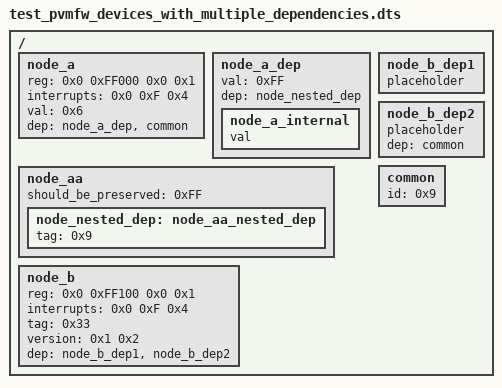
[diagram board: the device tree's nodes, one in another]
/dts-v1/;

/include/ "test_crosvm_dt_base.dtsi"

/ {
    node_a: node_a {
        reg = <0x0 0xFF000 0x0 0x1>;
        interrupts = <0x0 0xF 0x4>;
        val = <0x6>;
        dep = <&node_a_dep &common>;
    };

    node_a_dep: node_a_dep {
        val = <0xFF>;
        dep = <&node_nested_dep>;

        node_a_internal {
            val;
        };
    };

    node_aa {
        should_be_preserved = <0xFF>;
        node_nested_dep: node_aa_nested_dep {
            tag = <0x9>;
        };
    };

    node_b: node_b {
        reg = <0x0 0xFF100 0x0 0x1>;
        interrupts = <0x0 0xF 0x4>;
        tag = <0x33>;
        version = <0x1 0x2>;
        phandle = <0x5>;
        dep = <&node_b_dep1 &node_b_dep2>;
    };

    node_b_dep1: node_b_dep1 {
        placeholder;
    };

    node_b_dep2: node_b_dep2 {
        placeholder;
        dep = <&common>;
    };

    common: common {
        id = <0x9>;
    };
};
